# AT32F405 register map
Vendor: Keil; Series: AT32F405; File version: 1.0
CPU: CM4 r0p1, little endian, no MPU, FPU, 4 interrupt priority bits
Registers are 32-bit, read-write, reset 0x0 unless marked. A register's access mark holds for its fields unless they carry their own. Offsets are from the block's base; [hi:lo] are bit positions.

## I2C1 — Inter-integrated circuit
Base 0x40005400
Same registers: I2C2 0x40005800, I2C3 0x40005C00
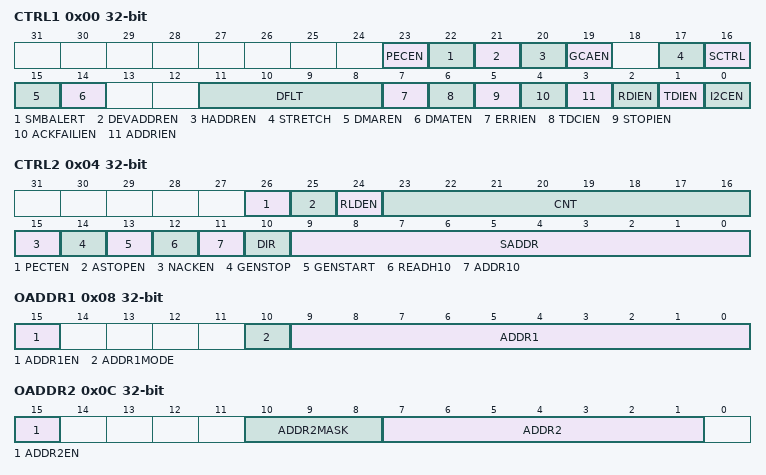
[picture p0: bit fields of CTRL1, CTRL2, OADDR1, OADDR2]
0x00 CTRL1 — Control register 1
  [23] PECEN — PEC calculation enable
  [22] SMBALERT — SMBus alert enable / pin set
  [21] DEVADDREN — SMBus device default address enable
  [20] HADDREN — SMBus host address enable
  [19] GCAEN — General call address enable
  [17] STRETCH — Clock stretching mode
  [16] SCTRL — Slave receiving data control
  [15] DMAREN — DMA receive data request enable
  [14] DMATEN — DMA Transmit data request enable
  [11:8] DFLT — Digital filter value
  [7] ERRIEN — Error interrupts enable
  [6] TDCIEN — Transfer data complete interrupt enable
  [5] STOPIEN — Stop generation complete interrupt enable
  [4] ACKFAILIEN — Acknowledge fail interrupt enable
  [3] ADDRIEN — Address match interrupt enable
  [2] RDIEN — Receive data interrupt enable
  [1] TDIEN — Transmit data interrupt enable
    on read: 0=Disabled (Data transmit data interrupt is disabled); 1=Enabled (Data transmit data interrupt is enabled) | on write: 0=Disable Data transmit data interrupt; 1=Enable Data transmit data interrupt
  [0] I2CEN — I2C peripheral enable
    on read: 0=Disabled (I2C peripheral is disabled); 1=Enabled (I2C peripheral is enabled) | on write: 0=Disable I2C peripheral; 1=Enable I2C peripheral
0x04 CTRL2 — Control register 2
  [26] PECTEN — Request PEC transmission enable
  [25] ASTOPEN — Automatically send stop condition enable
  [24] RLDEN — Send data reload mode enable
  [23:16] CNT — Transmit data counter
  [15] NACKEN — Not acknowledge enable
  [14] GENSTOP — Generate stop condition
  [13] GENSTART — Generate start condition
  [12] READH10 — 10-bit address header read enable
  [11] ADDR10 — Host send 10-bit address mode enable
  [10] DIR — Master data transmission direction
  [9:0] SADDR — Slave address
0x08 OADDR1 — Own address register 1
  [15] ADDR1EN — Own address 1 enable
  [10] ADDR1MODE — Own Address mode
  [9:0] ADDR1 — Interface address
0x0C OADDR2 — Own address register 2
  [15] ADDR2EN — Own address 2 enable
  [10:8] ADDR2MASK — Own address 2-bit mask
  [7:1] ADDR2 — Own address 2
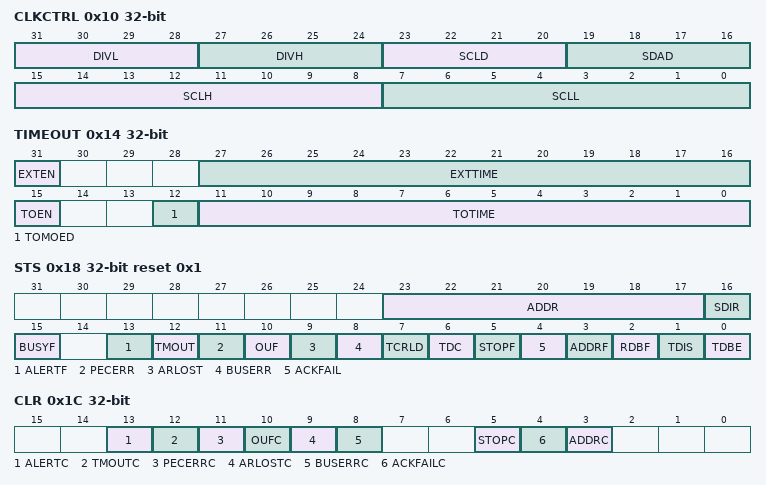
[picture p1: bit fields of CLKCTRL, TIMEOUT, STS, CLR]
0x10 CLKCTRL — Clock contorl register
  [31:28] DIVL — Low 4 bits of clock divider value
  [27:24] DIVH — High 4 bits of clock divider value
  [23:20] SCLD — SCL output delay
  [19:16] SDAD — SDA output delay
  [15:8] SCLH — SCL high level
  [7:0] SCLL — SCL low level
0x14 TIMEOUT
  [31] EXTEN — Cumulative clock low extend timeout enable
  [27:16] EXTTIME — Cumulative clock low extend timeout value
  [15] TOEN — Detect clock low/high timeout enable
  [12] TOMOED — Clock timeout detection mode
  [11:0] TOTIME — Clock timeout detection time
0x18 STS reset 0x1 — Interrupt and Status register
  [23:17] ADDR ro — Slave address matching value
  [16] SDIR ro — Slave data transmit direction
  [15] BUSYF ro — Bus busy
  [13] ALERTF ro — SMBus alert flag
  [12] TMOUT ro — SMBus timeout flag
  [11] PECERR ro — PEC receive error flag
  [10] OUF ro — Overflow or underflow flag
  [9] ARLOST ro — Arbitration lost flag
  [8] BUSERR ro — Bus error flag
  [7] TCRLD ro — Transmission is complete, waiting to load data
  [6] TDC ro — Transmit data complete flag
  [5] STOPF ro — Stop condition generation complete flag
  [4] ACKFAIL ro — Acknowledge failure flag
  [3] ADDRF ro — 0~7 bit address match flag
  [2] RDBF ro — Receive data buffer full flag
  [1] TDIS — Send interrupt status
  [0] TDBE — Transmit data buffer empty flag
0x1C CLR wo — Interrupt clear register
  [13] ALERTC — Clear SMBus alert flag
  [12] TMOUTC — Clear SMBus timeout flag
  [11] PECERRC — Clear PEC receive error flag
  [10] OUFC — Clear overload / underload flag
  [9] ARLOSTC — Clear arbitration lost flag
  [8] BUSERRC — Clear bus error flag
  [5] STOPC — Clear stop condition generation complete flag
  [4] ACKFAILC — Clear acknowledge failure flag
  [3] ADDRC — Clear 0~7 bit address match flag
0x20 PEC ro
  [7:0] PECVAL — PEC value
0x24 RXDT ro — Receive data register
  [7:0] DT
0x28 TXDT — Transmit data register
  [7:0] DT
